# psoc4100sp256kb register map
Vendor: Cypress Semiconductor; Series: PSoC4100Sp256KB; File version: 1.0
CPU: CM0PLUS r0p1, little endian, no MPU, no FPU, VTOR, 2 interrupt priority bits
Registers are 32-bit, read-write, reset 0x0 unless marked. A register's access mark holds for its fields unless they carry their own. Offsets are from the block's base; [hi:lo] are bit positions.

## WCO — 32KHz Oscillator
Base 0x40220000
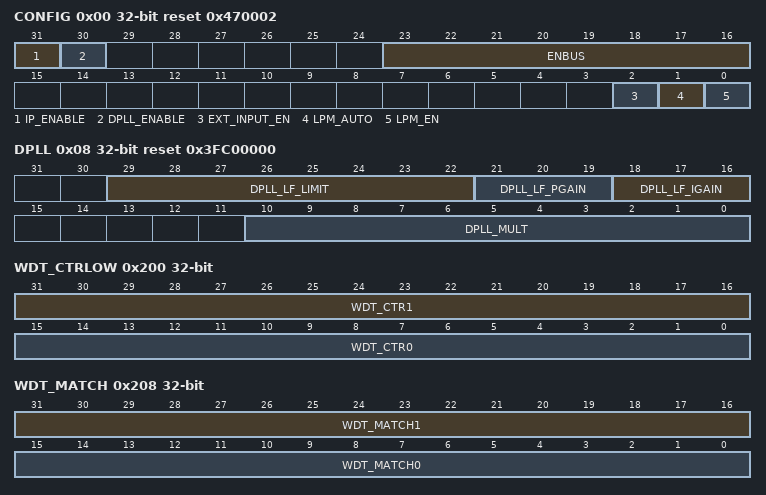
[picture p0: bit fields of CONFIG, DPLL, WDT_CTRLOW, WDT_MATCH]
0x00 CONFIG reset 0x470002 — WCO Configuration Register
  [31] IP_ENABLE — Master enable for IP - disables both WCO and DPLL
  [30] DPLL_ENABLE — Enable DPLL operation. The Oscillator is specified to be stable after 500 ms thus the DPLL should be asserted no sooner than that after IP_ENABLE is set.
  [23:16] ENBUS — Test Mode Control bits enbus[7] - N/A enbus[6] - 1=enable both primary Beta Multipliers enbus[5] - N/A enbus[4] - N/A enbus[3] - Load Resistor Control enbus[2] - Load Resistor Control enbus[1] - Load Resistor Control enbus[0] - Load Resistor Control
  [2] EXT_INPUT_EN — Disables the load resistor and allows external clock input for pad_xin
  [1] LPM_AUTO — Automatically control low power mode (only relevant when LPM_EN=0): 0: Do not enter low power mode (LPM) in DeepSleep 1: Enter low power mode (LPM) in DeepSleep. The logic monitors !act_power_en to determine the device has entered DeepSleep.
  [0] LPM_EN — Force block into Low Power Mode: 0: Do not force low power mode (LPM) on 1: Force low power mode (LPM) on
0x04 STATUS ro — WCO Status Register
  [0] OUT_BLNK_A — Indicates that output has transitioned - This bit is intended for Test Mode Only and is not a reliable indicator.
0x08 DPLL reset 0x3FC00000 — WCO DPLL Register
  [29:22] DPLL_LF_LIMIT — Maximum IMO offset allowed (used to prevent DPLL dynamics from selecting an IMO frequency that the logic cannot support)
  [21:19] DPLL_LF_PGAIN — DPLL Loop Filter Proportionial Gain Setting 0x0 - 0.0625 0x1 - 0.125 0x2 - 0.25 0x3 - 0.5 0x4 - 1.0 0x5 - 2.0 0x6 - 4.0 0x7 - 8.0
  [18:16] DPLL_LF_IGAIN — DPLL Loop Filter Integral Gain Setting 0x0 - 0.0625 0x1 - 0.125 0x2 - 0.25 0x3 - 0.5 0x4 - 1.0 0x5 - 2.0 0x6 - 4.0 0x7 - 8.0
  [10:0] DPLL_MULT — Multiplier to determine IMO frequency in multiples of the WCO frequency Fimo = (DPLL_MULT + 1) * Fwco
0x200 WDT_CTRLOW ro — Watchdog Counters 0/1
  [31:16] WDT_CTR1 — Current value of WDT Counter 1
  [15:0] WDT_CTR0 — Current value of WDT Counter 0
0x204 WDT_CTRHIGH ro — Watchdog Counter 2
  [31:0] WDT_CTR2 — Current value of WDT Counter 2
0x208 WDT_MATCH — Watchdog counter match values
  [31:16] WDT_MATCH1 — Match value for Watchdog Counter 1
  [15:0] WDT_MATCH0 — Match value for Watchdog Counter 0
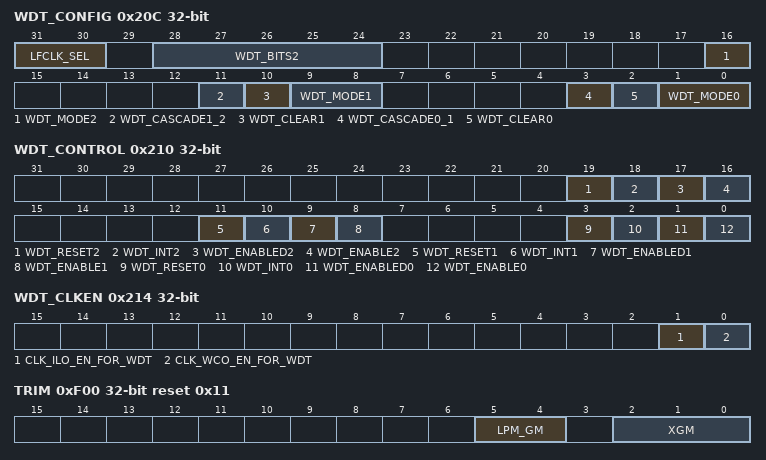
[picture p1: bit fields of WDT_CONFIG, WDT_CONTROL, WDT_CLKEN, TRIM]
0x20C WDT_CONFIG — Watchdog Counters Configuration
  [31:30] LFCLK_SEL
  [28:24] WDT_BITS2 — Bit to observe for WDT_INT2: 0: Assert when bit0 of WDT_CTR2 toggles (one int every tick) .. 31: Assert when bit31 of WDT_CTR2 toggles (one int every 2^31 ticks)
  [16] WDT_MODE2 — Watchdog Counter 2 Mode.
    0=NOTHING (Free running counter with no interrupt requests); 1=INT (Free running counter with interrupt request when a specified bit in CTR2 toggles (see WDT_BITS2))
  [11] WDT_CASCADE1_2 — Cascade Watchdog Counters 1,2. Counter 2 increments the cycle after WDT_CTR1=WDT_MATCH1. It is allowed to cascade all three WDT counters. 0: Independent counters 1: Cascaded counters. When cascading all three counters, WDT_CLEAR1 must be 1
  [10] WDT_CLEAR1 — Clear Watchdog Counter when WDT_CTR1=WDT_MATCH1. In other words WDT_CTR1 divides LFCLK by (WDT_MATCH1+1). 0: Free running counter 1: Clear on match
  [9:8] WDT_MODE1 — Watchdog Counter Action on Match (WDT_CTR1=WDT_MATCH1).
    0=NOTHING (Do nothing); 1=INT (Assert WDT_INTx); 2=RESET (Assert WDT Reset - Not Supported - here for backwards compatibility); 3=INT_THEN_RESET (Assert WDT_INTx, assert WDT Reset after 3rd unhandled interrupt - Not supported - here for backwards compatibility.)
  [3] WDT_CASCADE0_1 — Cascade Watchdog Counters 0,1. Counter 1 increments the cycle after WDT_CTR0=WDT_MATCH0. 0: Independent counters 1: Cascaded counters
  [2] WDT_CLEAR0 — Clear Watchdog Counter when WDT_CTR0=WDT_MATCH0. In other words WDT_CTR0 divides LFCLK by (WDT_MATCH0+1). 0: Free running counter 1: Clear on match
  [1:0] WDT_MODE0 — Watchdog Counter Action on Match (WDT_CTR0=WDT_MATCH0).
    0=NOTHING (Do nothing); 1=INT (Assert WDT_INTx); 2=RESET (Assert WDT Reset - Not Supported - here for backwards compatibility); 3=INT_THEN_RESET (Assert WDT_INTx, assert WDT Reset after 3rd unhandled interrupt. Not supported - here for Backwards compatibility.)
0x210 WDT_CONTROL — Watchdog Counters Control
  [19] WDT_RESET2 — Resets counter 2 back to 0000_0000. Hardware will reset this bit after counter was reset. This will take several LFCLK cycles to take effect. Wait until the reset completes before enabling the WDT.
  [18] WDT_INT2 — WDT Interrupt Request. This bit is set by hardware as configured by this registers. This bit must be cleared by firmware. After W1C, WDT_CONTROL must be read for the hardware to internally remove the clear flag. Failure to do this may result in missing the next interrupt.
  [17] WDT_ENABLED2 ro — Indicates actual state of counter. May lag WDT_ENABLE2 by up to 3 LFCLK cycles. After changing WDT_ENABLE2, do not enter DEEPSLEEP mode until this field acknowledges the change.
  [16] WDT_ENABLE2 — Enable Counter 2 0: Counter is disabled (not clocked) 1: Counter is enabled (counting up) Note: This field takes considerable time (up to 3 LFCLK cycles) to take effect. It must not be changed more than once in that period.
  [11] WDT_RESET1 — Resets counter 1 back to 0000. Hardware will reset this bit after counter was reset. This will take several LFCLK cycles to take effect. Wait until the reset completes before enabling the WDT.
  [10] WDT_INT1 — WDT Interrupt Request. This bit is set by hardware as configured by this registers. This bit must be cleared by firmware. After W1C, WDT_CONTROL must be read for the hardware to internally remove the clear flag. Failure to do this may result in missing the next interrupt.
  [9] WDT_ENABLED1 ro — Indicates actual state of counter. May lag WDT_ENABLE1 by up to 3 LFCLK cycles. After changing WDT_ENABLE1, do not enter DEEPSLEEP mode until this field acknowledges the change.
  [8] WDT_ENABLE1 — Enable Counter 1 0: Counter is disabled (not clocked) 1: Counter is enabled (counting up) Note: This field takes considerable time (up to 3 LFCLK cycles) to take effect. It must not be changed more than once in that period.
  [3] WDT_RESET0 — Resets counter 0 back to 0000. Hardware will reset this bit after counter was reset. This will take several LFCLK cycles to take effect. Wait until the reset completes before enabling the WDT.
  [2] WDT_INT0 — WDT Interrupt Request. This bit is set by hardware as configured by this registers. This bit must be cleared by firmware. Clearing this bit also prevents Reset from happening when WDT_MODEx=3. After W1C, WDT_CONTROL must be read for the hardware to internally remove the clear flag. Failure to do this may result in missing the next interrupt.
  [1] WDT_ENABLED0 ro — Indicates actual state of counter. May lag WDT_ENABLE0 by up to 3 LFCLK cycles. After changing WDT_ENABLE0, do not enter DEEPSLEEP mode until this field acknowledges the change.
  [0] WDT_ENABLE0 — Enable Counter 0 0: Counter is disabled (not clocked) 1: Counter is enabled (counting up) Note: This field takes considerable time (up to 3 LFCLK cycles) to take effect. It must not be changed more than once in that period.
0x214 WDT_CLKEN — Watchdog Counters Clock Enable
  [1] CLK_ILO_EN_FOR_WDT — Enables the ILO clock for use by the WDT logic. Wait at least 4 ILO clock cycles for a change to take effect. Must be 0 when switching WDT_CONFIG.LFCLK_SEL. Should be 0 if CLK_WCO_EN_FOR_WDT=1.
  [0] CLK_WCO_EN_FOR_WDT — Enables the WCO clock for use by the WDT logic. Wait at least 4 WCO clock cycles for a change to take effect. Must be 0 when switching WDT_CONFIG.LFCLK_SEL. Should be 0 if CLK_ILO_EN_FOR_WDT=1
0xF00 TRIM reset 0x11 — WCO Trim Register
  [5:4] LPM_GM — GM setting for LPM (bandwidth = DC/ms) - Used when WCO.LPM_AUTO=0 or when LPM_AUTO=1 and not in DeepSleep mode.
  [2:0] XGM — Amplifier GM setting - Used when WCO.LPM_AUTO=0 or when LPM_AUTO=1 and not in DeepSleep mode. 0x0 - 3370 nA 0x1 - 2620 nA 0x2 - 2250 nA 0x3 - 1500 nA 0x4 - 1870 nA 0x5 - 1120 nA 0x6 - 750 nA 0x7 - 0 nA

## Notices in the file
(c) (2016-2021), Cypress Semiconductor Corporation (an Infineon company)
or an affiliate of Cypress Semiconductor Corporation.
SPDX-License-Identifier: Apache-2.0
Licensed under the Apache License, Version 2.0 (the "License");
you may not use this file except in compliance with the License.
You may obtain a copy of the License at
http://www.apache.org/licenses/LICENSE-2.0
Unless required by applicable law or agreed to in writing, software
distributed under the License is distributed on an "AS IS" BASIS,
WITHOUT WARRANTIES OR CONDITIONS OF ANY KIND, either express or implied.
See the License for the specific language governing permissions and
limitations under the License.
